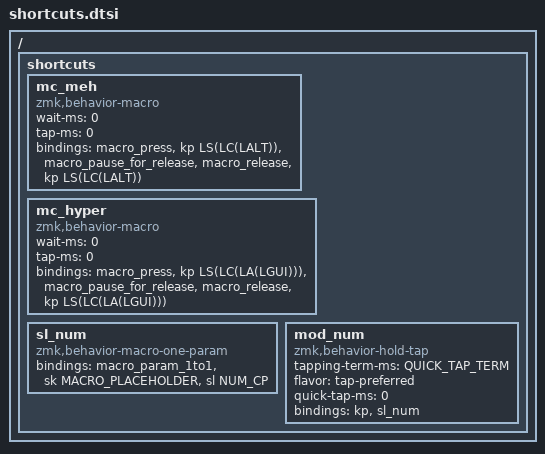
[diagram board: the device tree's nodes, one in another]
/*
*
* Copyright (c) 2022 Rafael Romão
* SPDX-License-Identifier: MIT
*
*/

/ {
    shortcuts {
        OS_MORPH(lm_os, &kp A, &kp D)

        MACRO(mc_sleep,                  &macro_tap_time 400 &macro_tap &kp C_SLEEP)

        MACRO(mc_caps,                   &macro_tap_time 100 &macro_tap &kp CAPS)
        MODTAP_TP(mt_caps,               &mc_caps)

        LAYERTAP_TP(lt_emoji,            &mc_emoji)

        // Shortcuts

        MACRO(mc_meh_b,                  &macro_tap &kp LC(LA(LS(B))))
        MACRO(mc_meh_m,                  &macro_tap &kp LC(LA(LS(M))))
        MACRO(mc_meh_g,                  &macro_tap &kp LC(LA(LS(G))))
        MACRO(mc_meh_l,                  &macro_tap &kp LC(LA(LS(L))))
        MACRO(mc_meh_o,                  &macro_tap &kp LC(LA(LS(O))))
        MACRO(mc_meh_u,                  &macro_tap &kp LC(LA(LS(U))))
        MACRO(mc_meh_n,                  &macro_tap &kp LC(LA(LS(N))))
        MACRO(mc_meh_s,                  &macro_tap &kp LC(LA(LS(S))))
        MACRO(mc_meh_t,                  &macro_tap &kp LC(LA(LS(T))))
        MACRO(mc_meh_r,                  &macro_tap &kp LC(LA(LS(R))))
        MACRO(mc_meh_a,                  &macro_tap &kp LC(LA(LS(A))))
        MACRO(mc_meh_e,                  &macro_tap &kp LC(LA(LS(E))))
        MACRO(mc_meh_f,                  &macro_tap &kp LC(LA(LS(F))))
        MODTAP_TP(mt_meh_f,              &mc_meh_f)
        MACRO(mc_meh_c,                  &macro_tap &kp LC(LA(LS(C))))
        MODTAP_TP(mt_meh_c,              &mc_meh_c)
        MACRO(mc_meh_p,                  &macro_tap &kp LC(LA(LS(P))))
        MODTAP_TP(mt_meh_p,              &mc_meh_p)
        MACRO(mc_meh_h,                  &macro_tap &kp LC(LA(LS(H))))
        MODTAP_TP(mt_meh_h,              &mc_meh_h)
        MACRO(mc_meh_w,                  &macro_tap &kp LC(LA(LS(W))))
        MACRO(mc_meh_v,                  &macro_tap &kp LC(LA(LS(V))))
        MACRO(mc_meh_z,                  &macro_tap &kp LC(LA(LS(Z))))
        MACRO(mc_meh_j,                  &macro_tap &kp LC(LA(LS(J))))
        MACRO(mc_meh_q,                  &macro_tap &kp LC(LA(LS(Q))))
        MACRO(mc_meh_k,                  &macro_tap &kp LC(LA(LS(K))))
        MACRO(mc_meh_x,                  &macro_tap &kp LC(LA(LS(X))))
        MACRO(mc_meh_y,                  &macro_tap &kp LC(LA(LS(Y))))
        MACRO(mc_meh_d,                  &macro_tap &kp LC(LA(LS(D))))
        MACRO(mc_meh_i,                  &macro_tap &kp LC(LA(LS(I))))

        // Navigation

        MACRO(mc_up_end_del,             &macro_tap &kp UP &kp END &kp DEL)
        MACRO(mc_down_end,               &macro_tap &kp DOWN &kp END)

        // Meh and Hyper

        MOD_MORPH_KM(mm_comma_meh, MOD_LSFT, &mc_meh_comma, &mc_comma)
        MOD_MORPH_KM(mm_comma_meh_lctl, MOD_LCTL, &mm_comma_meh, &mc_comma)
        MOD_MORPH_KM(mm_comma_meh_lalt, MOD_LALT, &mm_comma_meh_lctl, &mc_comma)

        MOD_MORPH_KM(mm_dot_meh, MOD_LSFT, &mc_meh_dot, &mc_dot)
        MOD_MORPH_KM(mm_dot_meh_lctl, MOD_LCTL, &mm_dot_meh, &mc_dot)
        MOD_MORPH_KM(mm_dot_meh_lalt, MOD_LALT, &mm_dot_meh_lctl, &mc_dot)

        MACRO(mc_meh_space,             &kp LS(LC(LA(SPACE))))
        MACRO(mc_hyper_space,           &kp LS(LC(LA(LG(SPACE)))))
        TAPHOLD_TP(th_hyper_space,      &mc_hyper_space, &mc_hyper)

        MACRO(mc_meh_enter,             &kp LS(LC(LA(ENTER))))
        MACRO(mc_hyper_enter,           &kp LS(LC(LA(LG(ENTER)))))
        TAPHOLD_TP(th_hyper_enter,      &mc_hyper_enter, &mc_hyper)

        LAYERTAP_TP(lt_cam,             &mc_cam)
        
        MACRO(mc_right,                 &kp RIGHT)
        LAYERTAP_TP(lt_right,           &mc_right)

        mc_meh: mc_meh {
            compatible = "zmk,behavior-macro";
            #binding-cells = <0>;
            wait-ms = <0>;
            tap-ms = <0>;
            bindings = <&macro_press &kp LS(LC(LALT)) &macro_pause_for_release &macro_release &kp LS(LC(LALT))>;
        };

        mc_hyper: mc_hyper {
            compatible = "zmk,behavior-macro";
            #binding-cells = <0>;
            wait-ms = <0>;
            tap-ms = <0>;
            bindings = <&macro_press &kp LS(LC(LA(LGUI))) &macro_pause_for_release &macro_release &kp LS(LC(LA(LGUI)))>;
        };

        TAPHOLD_TP(th_copy,       &mc_copy,     &mc_shift_copy)
        TAPHOLD_TP(th_selcopy,    &mc_selcopy,  &mc_shift_selcopy)
        TAPHOLD_TP(th_paste,      &mc_paste,    &mc_shift_paste)
        TAPHOLD_TP(th_selpaste,   &mc_selpaste, &mc_shift_selpaste)

        MACRO(mc_leader, &leader &to ALPHA1)
        
        MACRO(mc_home_tab,  &kp HOME &kp TAB)
        MACRO(mc_end_ent,   &kp END &kp ENTER)

        // Common

        OS_MORPH(mc_fullscr,           &macro_tap &kp LC(LG(F)),                                                                    &macro_tap &kp F11)
        OS_MORPH(mc_find,              &macro_tap &kp LG(F),                                                                        &macro_tap &kp LC(F))
        OS_MORPH(mc_selall,            &macro_tap &kp LG(A),                                                                        &macro_tap &kp LC(A))
        OS_MORPH(mc_undo,              &macro_tap &kp LG(Z),                                                                        &macro_tap &kp LC(Z))
        OS_MORPH(mc_copy,              &macro_tap &kp LG(C),                                                                        &macro_tap &kp LC(C))
        OS_MORPH(mc_shift_copy,        &macro_tap &kp LS(LG(C)),                                                                    &macro_tap &kp LS(LC(C)))
        OS_MORPH(mc_selcopy,           &macro_tap &kp LG(A) &kp LG(C),                                                              &macro_tap &kp LC(A) &kp LC(C))
        OS_MORPH(mc_shift_selcopy,     &macro_tap &kp LS(LG(A)) &kp LS(LG(C)),                                                      &macro_tap &kp LS(LC(A)) &kp LS(LC(C)))
        OS_MORPH(mc_paste,             &macro_tap &kp LG(V),                                                                        &macro_tap &kp LC(V))
        OS_MORPH(mc_shift_paste,       &macro_tap &kp LS(LG(V)),                                                                    &macro_tap &kp LS(LC(V)))
        OS_MORPH(mc_selpaste,          &macro_tap &kp LG(A) &kp LG(V),                                                              &macro_tap &kp LC(A) &kp LC(V))
        OS_MORPH(mc_shift_selpaste,    &macro_tap &kp LS(LG(A)) &kp LS(LG(V)),                                                      &macro_tap &kp LS(LC(A)) &kp LS(LC(V)))
        OS_MORPH(mc_save,              &macro_tap &kp LG(S),                                                                        &macro_tap &kp LC(S))
        OS_MORPH(mc_comment,           &macro_tap &kp LG(SLASH),                                                                    &macro_tap &kp LC(SLASH))
                                                                                                                             
        // Custom                                                                                                            
                                                                                                                             
        OS_MORPH(mc_lock,              &macro_tap &kp LC(LG(Q)),                                                                    &macro_tap &kp LG(L))
                                                                                                                             
        OS_MORPH(mc_refresh,           &macro_tap &kp LG(R),                                                                        &macro_tap &kp F5)
        OS_MORPH(mc_close,             &macro_tap &kp LG(W),                                                                        &macro_tap &kp LC(W))
        OS_MORPH(mc_reopen,            &macro_tap &kp LG(LS(T)),                                                                    &macro_tap &kp LC(LS(T)))
        OS_MORPH(mc_new,               &macro_tap &kp LG(T),                                                                        &macro_tap &kp LC(T))
                                                                                                                             
        OS_MORPH(mc_zoom_out,          &macro_tap &kp LG(MINUS),                                                                    &macro_tap &kp LC(MINUS))
        OS_MORPH(mc_zoom_in,           &macro_tap &kp LG(PLUS),                                                                     &macro_tap &kp LC(PLUS))
        OS_MORPH(mc_reset_zoom,        &macro_tap &kp LG(N0),                                                                       &macro_tap &kp LC(N0))
                                                                                                                             
        LAYERTAP_TP(lt_zoom_out,       &mc_zoom_out)
                                                                                                                             
        OS_MORPH(mc_swapper,           &macro_tap &kp LA(TAB),                                                                      &macro_tap &kp LA(TAB))
        OS_MORPH(mc_launcher,          &macro_tap &kp LA(SPACE),                                                                    &macro_tap &kp LA(SPACE))
        OS_MORPH(mc_tabs,              &macro_tap &kp LG(LS(A)),                                                                    &macro_tap &kp LC(LS(A)))
                                                                                                                             
        OS_MORPH(mc_files,             &macro_tap &kp LC(LA(F)),                                                                    &macro_tap &kp LG(E))
                                                                                                                             
        OS_MORPH(mc_hand,              &macro_tap &kp LC(LA(H)),                                                                    &macro_tap &kp LC(LA(H)))
        OS_MORPH(mc_mic,               &macro_tap &kp LC(LA(D)),                                                                    &macro_tap &kp LC(LA(D)))
        OS_MORPH(mc_cam,               &macro_tap &kp LC(LA(E)),                                                                    &macro_tap &kp LC(LA(E)))
        OS_MORPH(mc_screenshot,        &macro_tap &kp LC(LA(S)),                                                                    &macro_tap &kp LC(LA(S)))
        OS_MORPH(mc_emoji,             &macro_tap &kp LC(LA(J)),                                                                    &macro_tap &kp LC(LA(J)))
        OS_MORPH(mc_calc,              &macro_tap &kp LC(LA(C)),                                                                    &macro_tap &kp LC(LA(C)))
        OS_MORPH(mc_notes,             &macro_tap &kp LC(LA(O)),                                                                    &macro_tap &kp LC(LA(O)))
        OS_MORPH(mc_term,              &macro_tap &kp LC(LA(T)),                                                                    &macro_tap &kp LC(LA(T)))
        OS_MORPH(mc_browser,           &macro_tap &kp LC(LA(B)),                                                                    &macro_tap &kp LC(LA(B)))
        OS_MORPH(mc_editor,            &macro_tap &kp LC(LA(N)),                                                                    &macro_tap &kp LC(LA(N)))
        OS_MORPH(mc_ai,                &macro_tap &kp LC(LA(I)),                                                                    &macro_tap &kp LC(LA(I)))
        OS_MORPH(mc_activities,        &macro_tap &kp LC(LA(A)),                                                                    &macro_tap &kp LC(LA(A)))
        OS_MORPH(mc_system,            &macro_tap &kp LC(SPACE),                                                                    &macro_tap &kp LC(SPACE))
        OS_MORPH(mc_containers,        &macro_tap &kp LC(LA(R)),                                                                    &macro_tap &kp LC(LA(R)))

        LAYERTAP_TP(lt_system,         &mc_system)

                                                                                                                             
        // Navigation                                                                                                        
                                                                                                                             
        OS_MORPH(mc_prev_word,         &macro_tap &kp LA(LEFT),                                                                     &macro_tap &kp LC(LEFT))
        OS_MORPH(mc_next_word,         &macro_tap &kp LA(RIGHT),                                                                    &macro_tap &kp LC(RIGHT))
        OS_MORPH(mc_del_word,          &macro_press &kp LA(DELETE) &macro_pause_for_release &macro_release &kp LA(DELETE),          &macro_press &kp LC(DELETE) &macro_pause_for_release &macro_release &kp LC(DELETE))
        OS_MORPH(mc_bsp_word,          &macro_press &kp LA(BACKSPACE) &macro_pause_for_release &macro_release &kp LA(BACKSPACE),    &macro_press &kp LC(BACKSPACE) &macro_pause_for_release &macro_release &kp LC(BACKSPACE))
                                                                                                                             
        // Meh and Hyper                                                                                                     
                                                                                                                             
        OS_MORPH(mc_meh_comma,         &macro_tap &kp LC(LA(LS(SQT))),                                                              &macro_tap &kp LC(LA(LS(COMMA))))
        OS_MORPH(mc_meh_dot,           &macro_tap &kp LC(LA(LS(BACKSLASH))),                                                        &macro_tap &kp LC(LA(LS(DOT))))

        MODTAP_TP(mt_meh_comm,         &mc_meh_comma)
        MODTAP_TP(mt_meh_dot,          &mc_meh_dot)

        sl_num: sl_num {
            compatible = "zmk,behavior-macro-one-param";
            #binding-cells = <1>;
            bindings = <&macro_param_1to1>, <&sk MACRO_PLACEHOLDER>, <&sl NUM_CP>;
        };

        mod_num: mod_num {
            compatible = "zmk,behavior-hold-tap";
            #binding-cells = <2>;
            tapping-term-ms = <QUICK_TAP_TERM>;
            flavor = "tap-preferred";
            quick-tap-ms = <0>;
            bindings = <&kp>, <&sl_num>;
        };

   };
};
